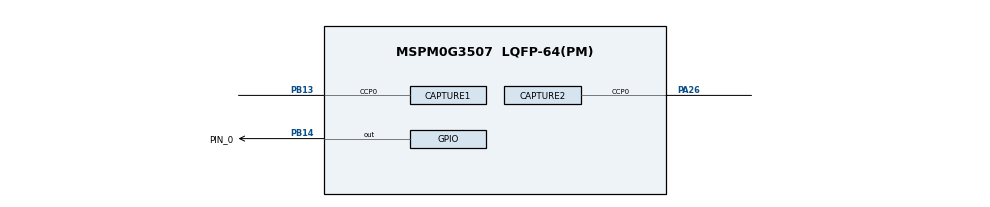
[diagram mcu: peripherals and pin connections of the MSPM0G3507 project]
/**
 * AI AGENTS: Do not edit this file directly. There is no validation or error feedback when
 * editing manually â€?mistakes will be silent until the file is loaded in SysConfig.
 * Use the SysConfig MCP server instead to make changes with immediate error reporting.
 *
 * These arguments were used when this file was generated. They will be automatically applied on subsequent loads
 * via the GUI or CLI. Run CLI with '--help' for additional information on how to override these arguments.
 * @cliArgs --device "MSPM0G350X" --part "Default" --package "LQFP-64(PM)" --product "mspm0_sdk@2.09.00.00"
 * @v2CliArgs --device "MSPM0G3507" --package "LQFP-64(PM)" --product "mspm0_sdk@2.09.00.00"
 * @versions {"tool":"1.28.0+4712"}
 */

/**
 * Import the modules used in this configuration.
 */
const ADC12         = scripting.addModule("/ti/driverlib/ADC12", {}, false);
const ADC121        = ADC12.addInstance();
const CAPTURE       = scripting.addModule("/ti/driverlib/CAPTURE", {}, false);
const CAPTURE1      = CAPTURE.addInstance();
const CAPTURE2      = CAPTURE.addInstance();
const CRC           = scripting.addModule("/ti/driverlib/CRC");
const DMA           = scripting.addModule("/ti/driverlib/DMA");
const GPIO          = scripting.addModule("/ti/driverlib/GPIO", {}, false);
const GPIO1         = GPIO.addInstance();
const I2C           = scripting.addModule("/ti/driverlib/I2C", {}, false);
const I2C1          = I2C.addInstance();
const PWM           = scripting.addModule("/ti/driverlib/PWM", {}, false);
const PWM1          = PWM.addInstance();
const PWM2          = PWM.addInstance();
const PWM3          = PWM.addInstance();
const PWM4          = PWM.addInstance();
const SPI           = scripting.addModule("/ti/driverlib/SPI", {}, false);
const SPI1          = SPI.addInstance();
const SYSCTL        = scripting.addModule("/ti/driverlib/SYSCTL");
const SYSTICK       = scripting.addModule("/ti/driverlib/SYSTICK");
const TIMER         = scripting.addModule("/ti/driverlib/TIMER", {}, false);
const TIMER1        = TIMER.addInstance();
const UART          = scripting.addModule("/ti/driverlib/UART", {}, false);
const UART1         = UART.addInstance();
const ProjectConfig = scripting.addModule("/ti/project_config/ProjectConfig");

/**
 * Write custom configuration values to the imported modules.
 */
const divider6       = system.clockTree["PLL_CLK2X_DIV"];
divider6.divideValue = 4;

const divider9       = system.clockTree["UDIV"];
divider9.divideValue = 2;

const multiplier2         = system.clockTree["PLL_QDIV"];
multiplier2.multiplyValue = 5;

const mux8       = system.clockTree["HSCLKMUX"];
mux8.inputSelect = "HSCLKMUX_SYSPLL2X";

ADC121.$name                      = "ADC12_0";
ADC121.powerDownMode              = "DL_ADC12_POWER_DOWN_MODE_MANUAL";
ADC121.sampleTime0                = "1 us";
ADC121.peripheral.adcPin0.$assign = "PA15";
ADC121.adcPin0Config.$name        = "ti_driverlib_gpio_GPIOPinGeneric0";

const Board = scripting.addModule("/ti/driverlib/Board", {}, false);

CAPTURE1.$name                      = "CAPTURE_0";
CAPTURE1.timerPeriod                = "1 ms";
CAPTURE1.peripheral.$assign         = "TIMG12";
CAPTURE1.peripheral.ccp0Pin.$assign = "PB13";
CAPTURE1.ccp0PinConfig.$name        = "ti_driverlib_gpio_GPIOPinGeneric17";

CAPTURE2.$name                      = "CAPTURE_1";
CAPTURE2.timerPeriod                = "1 ms";
CAPTURE2.peripheral.$assign         = "TIMG8";
CAPTURE2.peripheral.ccp0Pin.$assign = "PA26";
CAPTURE2.ccp0PinConfig.$name        = "ti_driverlib_gpio_GPIOPinGeneric18";


GPIO1.$name                          = "GPIO_GRP_0";
GPIO1.port                           = "PORTB";
GPIO1.portSegment                    = "Lower";
GPIO1.associatedPins[0].$name        = "PIN_0";
GPIO1.associatedPins[0].initialValue = "SET";
GPIO1.associatedPins[0].ioStructure  = "SD";
GPIO1.associatedPins[0].pin.$assign  = "PB14";

I2C1.$name                     = "I2C_0";
I2C1.sdaPinConfig.$name        = "ti_driverlib_gpio_GPIOPinGeneric1";
I2C1.sdaPinConfig.enableConfig = true;
I2C1.sclPinConfig.$name        = "ti_driverlib_gpio_GPIOPinGeneric2";
I2C1.sclPinConfig.enableConfig = true;

PWM1.$name                 = "PWM_0";
PWM1.timerCount            = 4000;
PWM1.PWM_CHANNEL_0.$name   = "ti_driverlib_pwm_PWMTimerCC0";
PWM1.PWM_CHANNEL_0.ccValue = 0;
PWM1.PWM_CHANNEL_1.$name   = "ti_driverlib_pwm_PWMTimerCC1";
PWM1.ccp0PinConfig.$name   = "ti_driverlib_gpio_GPIOPinGeneric9";
PWM1.ccp1PinConfig.$name   = "ti_driverlib_gpio_GPIOPinGeneric10";

PWM2.$name                 = "PWM_1";
PWM2.timerCount            = 4000;
PWM2.PWM_CHANNEL_0.$name   = "ti_driverlib_pwm_PWMTimerCC2";
PWM2.PWM_CHANNEL_0.ccValue = 0;
PWM2.PWM_CHANNEL_1.$name   = "ti_driverlib_pwm_PWMTimerCC3";
PWM2.ccp0PinConfig.$name   = "ti_driverlib_gpio_GPIOPinGeneric11";
PWM2.ccp1PinConfig.$name   = "ti_driverlib_gpio_GPIOPinGeneric12";

PWM3.$name                 = "PWM_2";
PWM3.timerCount            = 2000;
PWM3.PWM_CHANNEL_0.$name   = "ti_driverlib_pwm_PWMTimerCC4";
PWM3.PWM_CHANNEL_0.ccValue = 0;
PWM3.PWM_CHANNEL_1.$name   = "ti_driverlib_pwm_PWMTimerCC5";
PWM3.ccp0PinConfig.$name   = "ti_driverlib_gpio_GPIOPinGeneric13";
PWM3.ccp1PinConfig.$name   = "ti_driverlib_gpio_GPIOPinGeneric14";

PWM4.$name                 = "PWM_3";
PWM4.timerCount            = 4000;
PWM4.PWM_CHANNEL_0.$name   = "ti_driverlib_pwm_PWMTimerCC6";
PWM4.PWM_CHANNEL_0.ccValue = 0;
PWM4.PWM_CHANNEL_1.$name   = "ti_driverlib_pwm_PWMTimerCC7";
PWM4.ccp0PinConfig.$name   = "ti_driverlib_gpio_GPIOPinGeneric15";
PWM4.ccp1PinConfig.$name   = "ti_driverlib_gpio_GPIOPinGeneric16";

SPI1.$name               = "SPI_0";
SPI1.frameFormat         = "MOTO3";
SPI1.sclkPinConfig.$name = "ti_driverlib_gpio_GPIOPinGeneric3";
SPI1.mosiPinConfig.$name = "ti_driverlib_gpio_GPIOPinGeneric4";
SPI1.misoPinConfig.$name = "ti_driverlib_gpio_GPIOPinGeneric5";

SYSCTL.clockTreeEn       = true;
SYSCTL.validateClkStatus = true;

TIMER1.$name            = "TIMER_0";
TIMER1.timerClkPrescale = 80;
TIMER1.timerMode        = "PERIODIC";
TIMER1.timerPeriod      = "1 ms";

UART1.$name                      = "UART_0";
UART1.targetBaudRate             = 115200;
UART1.enabledDMARXTriggers       = "DL_UART_DMA_INTERRUPT_RX";
UART1.enabledDMATXTriggers       = "DL_UART_DMA_INTERRUPT_TX";
UART1.enableFIFO                 = true;
UART1.rxFifoThreshold            = "DL_UART_RX_FIFO_LEVEL_ONE_ENTRY";
UART1.txFifoThreshold            = "DL_UART_TX_FIFO_LEVEL_ONE_ENTRY";
UART1.enabledInterrupts          = ["BREAK_ERROR","DMA_DONE_RX","DMA_DONE_TX","EOT_DONE","FRAMING_ERROR","NOISE_ERROR","OVERRUN_ERROR","PARITY_ERROR"];
UART1.txPinConfig.$name          = "ti_driverlib_gpio_GPIOPinGeneric7";
UART1.rxPinConfig.$name          = "ti_driverlib_gpio_GPIOPinGeneric8";
UART1.DMA_CHANNEL_RX.$name       = "DMA_CH0";
UART1.DMA_CHANNEL_RX.srcLength   = "BYTE";
UART1.DMA_CHANNEL_RX.addressMode = "f2b";
UART1.DMA_CHANNEL_RX.dstLength   = "BYTE";
UART1.DMA_CHANNEL_TX.$name       = "DMA_CH1";
UART1.DMA_CHANNEL_TX.addressMode = "b2f";
UART1.DMA_CHANNEL_TX.srcLength   = "BYTE";
UART1.DMA_CHANNEL_TX.dstLength   = "BYTE";

ProjectConfig.genLibCMSIS = true;

/**
 * Pinmux solution for unlocked pins/peripherals. This ensures that minor changes to the automatic solver in a future
 * version of the tool will not impact the pinmux you originally saw.  These lines can be completely deleted in order to
 * re-solve from scratch.
 */
ADC121.peripheral.$suggestSolution               = "ADC1";
Board.peripheral.$suggestSolution                = "DEBUGSS";
Board.peripheral.swclkPin.$suggestSolution       = "PA20";
Board.peripheral.swdioPin.$suggestSolution       = "PA19";
CRC.peripheral.$suggestSolution                  = "CRC";
I2C1.peripheral.$suggestSolution                 = "I2C0";
I2C1.peripheral.sdaPin.$suggestSolution          = "PA28";
I2C1.peripheral.sclPin.$suggestSolution          = "PA31";
PWM1.peripheral.$suggestSolution                 = "TIMG7";
PWM1.peripheral.ccp0Pin.$suggestSolution         = "PA23";
PWM1.peripheral.ccp1Pin.$suggestSolution         = "PA18";
PWM2.peripheral.$suggestSolution                 = "TIMG6";
PWM2.peripheral.ccp0Pin.$suggestSolution         = "PA21";
PWM2.peripheral.ccp1Pin.$suggestSolution         = "PA22";
PWM3.peripheral.$suggestSolution                 = "TIMG0";
PWM3.peripheral.ccp0Pin.$suggestSolution         = "PA12";
PWM3.peripheral.ccp1Pin.$suggestSolution         = "PA13";
PWM4.peripheral.$suggestSolution                 = "TIMA1";
PWM4.peripheral.ccp0Pin.$suggestSolution         = "PA17";
PWM4.peripheral.ccp1Pin.$suggestSolution         = "PA16";
SPI1.peripheral.$suggestSolution                 = "SPI0";
SPI1.peripheral.sclkPin.$suggestSolution         = "PA11";
SPI1.peripheral.mosiPin.$suggestSolution         = "PA14";
SPI1.peripheral.misoPin.$suggestSolution         = "PA10";
TIMER1.peripheral.$suggestSolution               = "TIMA0";
UART1.peripheral.$suggestSolution                = "UART0";
UART1.peripheral.rxPin.$suggestSolution          = "PA1";
UART1.peripheral.txPin.$suggestSolution          = "PA0";
UART1.DMA_CHANNEL_RX.peripheral.$suggestSolution = "DMA_CH1";
UART1.DMA_CHANNEL_TX.peripheral.$suggestSolution = "DMA_CH0";
